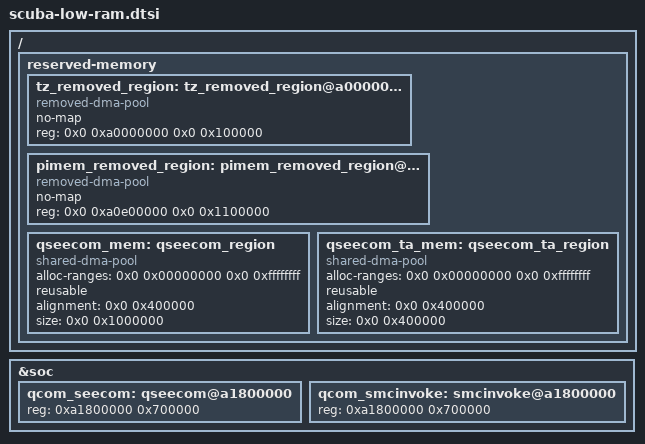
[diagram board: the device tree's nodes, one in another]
#include "scuba.dtsi"
/ {
	reserved-memory {
		/delete-node/ removed_region@a0000000;
		/delete-node/ qseecom_region;
		/delete-node/ qseecom_ta_region;

		tz_removed_region: tz_removed_region@a0000000 {
			compatible = "removed-dma-pool";
			no-map;
			reg = <0x0 0xa0000000 0x0 0x100000>;
		};

		pimem_removed_region: pimem_removed_region@a0e00000 {
			compatible = "removed-dma-pool";
			no-map;
			reg = <0x0 0xa0e00000 0x0 0x1100000>;
		};

		qseecom_mem: qseecom_region {
			compatible = "shared-dma-pool";
			alloc-ranges = <0x0 0x00000000 0x0 0xffffffff>;
			reusable;
			alignment = <0x0 0x400000>;
			size = <0x0 0x1000000>;
		};

		qseecom_ta_mem: qseecom_ta_region {
			compatible = "shared-dma-pool";
			alloc-ranges = <0x0 0x00000000 0x0 0xffffffff>;
			reusable;
			alignment = <0x0 0x400000>;
			size = <0x0 0x400000>;
		};
	};
};

&soc {
	qcom_seecom: qseecom@a1800000 {
		reg = <0xa1800000 0x700000>;
	};

	qcom_smcinvoke: smcinvoke@a1800000 {
		reg = <0xa1800000 0x700000>;
	};
};
